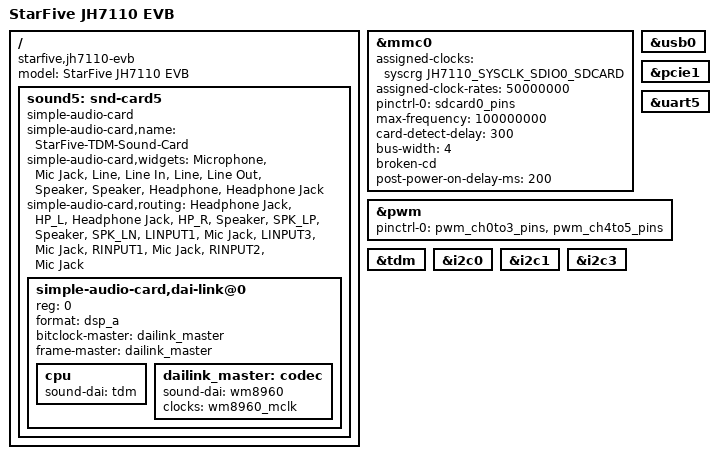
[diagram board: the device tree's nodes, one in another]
// SPDX-License-Identifier: GPL-2.0 OR MIT
/*
 * Copyright (C) 2022 StarFive Technology Co., Ltd.
 */

/dts-v1/;
#include "jh7110-evb.dtsi"

/ {
	model = "StarFive JH7110 EVB";
	compatible = "starfive,jh7110-evb", "starfive,jh7110";

	sound5: snd-card5 {
		compatible = "simple-audio-card";
		#address-cells = <1>;
		#size-cells = <0>;

		simple-audio-card,name = "StarFive-TDM-Sound-Card";
		simple-audio-card,widgets = "Microphone", "Mic Jack",
					    "Line", "Line In",
					    "Line", "Line Out",
					    "Speaker", "Speaker",
					    "Headphone", "Headphone Jack";
		simple-audio-card,routing = "Headphone Jack", "HP_L",
					    "Headphone Jack", "HP_R",
					    "Speaker", "SPK_LP",
					    "Speaker", "SPK_LN",
					    "LINPUT1", "Mic Jack",
					    "LINPUT3", "Mic Jack",
					    "RINPUT1", "Mic Jack",
					    "RINPUT2", "Mic Jack";

		simple-audio-card,dai-link@0 {
			reg = <0>;
			format = "dsp_a";
			bitclock-master = <&dailink_master>;
			frame-master = <&dailink_master>;

			cpu {
				sound-dai = <&tdm>;
			};
			dailink_master: codec {
				sound-dai = <&wm8960>;
				clocks = <&wm8960_mclk>;
			};
		};
	};
};

&mmc0 {
	assigned-clocks = <&syscrg JH7110_SYSCLK_SDIO0_SDCARD>;
	assigned-clock-rates = <50000000>;
	pinctrl-names = "default";
	pinctrl-0 = <&sdcard0_pins>;
	max-frequency = <100000000>;
	card-detect-delay = <300>;
	bus-width = <4>;
	broken-cd;
	post-power-on-delay-ms = <200>;
	status = "okay";
};

&usb0 {
	status = "okay";
};

&pcie1 {
	status = "okay";
};

&uart5 {
	status = "okay";
};

&pwm {
	pinctrl-names = "default";
	pinctrl-0 = <&pwm_ch0to3_pins &pwm_ch4to5_pins>;
	status = "okay";
};

&tdm {
	status = "okay";
};

&i2c0 {
	status = "okay";
};

&i2c1 {
	status = "okay";
};

&i2c3 {
	status = "okay";
};
